AUTOSAR XML (schema 4-2-2)
package /EB/SoftwareComponents
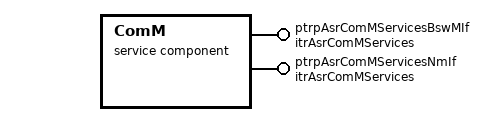
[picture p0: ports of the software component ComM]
  service sw component type ComM: category=ASR_Interfaces
    provide port ptrpAsrComMServicesBswMIf: provided-interface=itrAsrComMServices
    provide port ptrpAsrComMServicesNmIf: provided-interface=itrAsrComMServices
    behavior ComM_IB: handle-termination-and-restart=NO-SUPPORT
      4 x runnable:
        ComM_ASR40_RequestComMode
        ComM_CommunicationAllowed
        ComM_DeInit
        ComM_Init
package /EB/TriggerInterfaces
  trigger interface itrAsrComMServices
    4 x trigger, all with trigger-period={cse-code=1000, cse-code-factor=0}:
      ComM_ASR40_RequestComMode
      ComM_CommunicationAllowed
      ComM_DeInit
      ComM_Init
